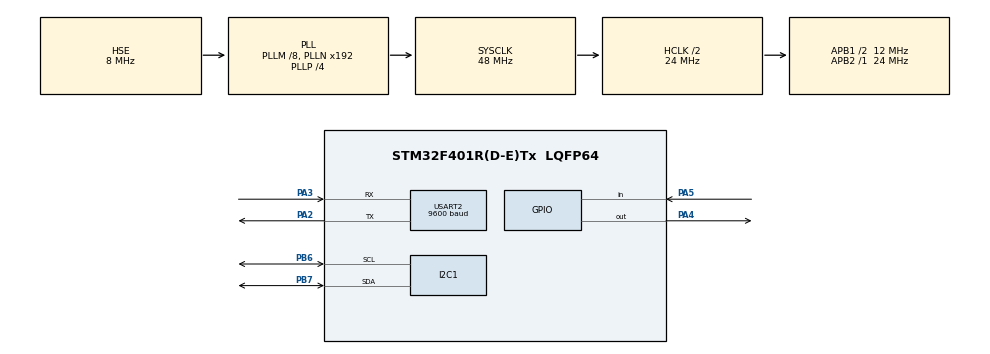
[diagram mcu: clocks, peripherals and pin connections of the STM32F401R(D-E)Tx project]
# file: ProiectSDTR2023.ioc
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FREERTOS.Tasks01=Task1,40,128,StartTask1,Default,NULL,Dynamic,NULL,NULL;Task2,24,128,StartTask2,Default,NULL,Dynamic,NULL,NULL
FREERTOS.configUSE_NEWLIB_REENTRANT=1
I2C1.I2C_Mode=I2C_Fast
Mcu.Family=STM32F4
Mcu.Name=STM32F401R(D-E)Tx
Mcu.Package=LQFP64
NVIC.PriorityGroup=NVIC_PRIORITYGROUP_4
NVIC.TIM5_IRQn=true\:15\:0\:false\:false\:true\:false\:false\:true\:true
NVIC.TimeBase=TIM5_IRQn
NVIC.TimeBaseIP=TIM5
PA13.Mode=Trace_Asynchronous_SW
PA13.Signal=SYS_JTMS-SWDIO
PA14.Mode=Trace_Asynchronous_SW
PA14.Signal=SYS_JTCK-SWCLK
PA2.Mode=Asynchronous
PA2.Signal=USART2_TX
PA3.Mode=Asynchronous
PA3.Signal=USART2_RX
PA4.Signal=GPIO_Output
PA5.Signal=GPIO_Input
PB3.Mode=Trace_Asynchronous_SW
PB3.Signal=SYS_JTDO-SWO
PB6.Mode=I2C
PB6.Signal=I2C1_SCL
PB7.Mode=I2C
PB7.Signal=I2C1_SDA
PH0\ -\ OSC_IN.Mode=HSE-External-Oscillator
PH0\ -\ OSC_IN.Signal=RCC_OSC_IN
PH1\ -\ OSC_OUT.Mode=HSE-External-Oscillator
PH1\ -\ OSC_OUT.Signal=RCC_OSC_OUT
ProjectManager.HeapSize=0x200
ProjectManager.StackSize=0x400
ProjectManager.TargetToolchain=STM32CubeIDE
RCC.48MHZClocksFreq_Value=48000000
RCC.AHBCLKDivider=RCC_SYSCLK_DIV2
RCC.AHBFreq_Value=24000000
RCC.APB1CLKDivider=RCC_HCLK_DIV2
RCC.APB1Freq_Value=12000000
RCC.APB1TimFreq_Value=24000000
RCC.APB2Freq_Value=24000000
RCC.APB2TimFreq_Value=24000000
RCC.CortexFreq_Value=24000000
RCC.HCLKFreq_Value=24000000
RCC.HSE_VALUE=8000000
RCC.HSI_VALUE=16000000
RCC.LSE_VALUE=32768
RCC.PLLM=8
RCC.PLLP=RCC_PLLP_DIV4
RCC.PLLSourceVirtual=RCC_PLLSOURCE_HSE
RCC.SYSCLKFreq_VALUE=48000000
RCC.SYSCLKSource=RCC_SYSCLKSOURCE_PLLCLK
RCC.VCOOutputFreq_Value=192000000
TIM1.Prescaler=71
USART2.BaudRate=9600
USART2.VirtualMode=VM_ASYNC
VP_FREERTOS_VS_CMSIS_V2.Mode=CMSIS_V2
VP_SYS_VS_tim5.Mode=TIM5
VP_TIM1_VS_ClockSourceINT.Mode=Internal
board=custom

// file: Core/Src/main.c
/* USER CODE BEGIN Header */
/**
  ******************************************************************************
  * @file           : main.c
  * @brief          : Main program body
  ******************************************************************************
  * @attention
  *
  * Copyright (c) 2023 STMicroelectronics.
  * All rights reserved.
  *
  * This software is licensed under terms that can be found in the LICENSE file
  * in the root directory of this software component.
  * If no LICENSE file comes with this software, it is provided AS-IS.
  *
  ******************************************************************************
  */
/* USER CODE END Header */
#include "main.h"
#include "cmsis_os.h"
#include "string.h"

/* USER CODE BEGIN Includes */
#include <stdio.h>

/* USER CODE END Includes */

I2C_HandleTypeDef hi2c1;

TIM_HandleTypeDef htim1;

UART_HandleTypeDef huart2;

/* Definitions for Task1 */
osThreadId_t Task1Handle;
const osThreadAttr_t Task1_attributes = {
  .name = "Task1",
  .stack_size = 128 * 4,
  .priority = (osPriority_t) osPriorityHigh,
};
/* Definitions for Task2 */
osThreadId_t Task2Handle;
const osThreadAttr_t Task2_attributes = {
  .name = "Task2",
  .stack_size = 128 * 4,
  .priority = (osPriority_t) osPriorityNormal,
};
/* USER CODE BEGIN PV */
osSemaphoreId_t distanceSemaphoreHandle;
osMessageQueueId_t distanceQueueHandle;
/* USER CODE END PV */

void SystemClock_Config(void);
static void MX_GPIO_Init(void);
static void MX_USART2_UART_Init(void);
static void MX_I2C1_Init(void);
static void MX_TIM1_Init(void);
void StartTask1(void *argument);
void StartTask2(void *argument);

int main(void)
{

  /* MCU Configuration--------------------------------------------------------*/

  /* Reset of all peripherals, Initializes the Flash interface and the Systick. */

	HAL_Init();

  /* Configure the system clock */
  SystemClock_Config();

  /* Initialize all configured peripherals */
  MX_GPIO_Init();
  MX_USART2_UART_Init();
  MX_I2C1_Init();
  MX_TIM1_Init();
  HAL_TIM_Base_Start(&htim1);

  /* Init scheduler */
  osKernelInitialize();

  /* USER CODE BEGIN RTOS_SEMAPHORES */
  distanceSemaphoreHandle = osSemaphoreNew(1, 0, NULL);
  /* USER CODE END RTOS_SEMAPHORES */

  /* USER CODE BEGIN RTOS_QUEUES */
  distanceQueueHandle = osMessageQueueNew(1, sizeof(uint32_t), NULL);
  /* USER CODE END RTOS_QUEUES */

  /* Create the thread(s) */
  /* creation of Task1 */
  Task1Handle = osThreadNew(StartTask1, NULL, &Task1_attributes);

  /* creation of Task2 */
  Task2Handle = osThreadNew(StartTask2, NULL, &Task2_attributes);

  /* Start scheduler */

  osKernelStart();

  /* We should never get here as control is now taken by the scheduler */
  /* Infinite loop */
  while (1)
  {

  }
}

void SystemClock_Config(void)
{
  RCC_OscInitTypeDef RCC_OscInitStruct = {0};
  RCC_ClkInitTypeDef RCC_ClkInitStruct = {0};

  /** Configure the main internal regulator output voltage
  */
  __HAL_RCC_PWR_CLK_ENABLE();
  __HAL_PWR_VOLTAGESCALING_CONFIG(PWR_REGULATOR_VOLTAGE_SCALE2);

  /** Initializes the RCC Oscillators according to the specified parameters
  * in the RCC_OscInitTypeDef structure.
  */
  RCC_OscInitStruct.OscillatorType = RCC_OSCILLATORTYPE_HSE;
  RCC_OscInitStruct.HSEState = RCC_HSE_ON;
  RCC_OscInitStruct.PLL.PLLState = RCC_PLL_ON;
  RCC_OscInitStruct.PLL.PLLSource = RCC_PLLSOURCE_HSE;
  RCC_OscInitStruct.PLL.PLLM = 8;
  RCC_OscInitStruct.PLL.PLLN = 192;
  RCC_OscInitStruct.PLL.PLLP = RCC_PLLP_DIV4;
  RCC_OscInitStruct.PLL.PLLQ = 4;
  if (HAL_RCC_OscConfig(&RCC_OscInitStruct) != HAL_OK)
  {
    Error_Handler();
  }

  /** Initializes the CPU, AHB and APB buses clocks
  */
  RCC_ClkInitStruct.ClockType = RCC_CLOCKTYPE_HCLK|RCC_CLOCKTYPE_SYSCLK
                              |RCC_CLOCKTYPE_PCLK1|RCC_CLOCKTYPE_PCLK2;
  RCC_ClkInitStruct.SYSCLKSource = RCC_SYSCLKSOURCE_PLLCLK;
  RCC_ClkInitStruct.AHBCLKDivider = RCC_SYSCLK_DIV2;
  RCC_ClkInitStruct.APB1CLKDivider = RCC_HCLK_DIV2;
  RCC_ClkInitStruct.APB2CLKDivider = RCC_HCLK_DIV1;

  if (HAL_RCC_ClockConfig(&RCC_ClkInitStruct, FLASH_LATENCY_0) != HAL_OK)
  {
    Error_Handler();
  }
}

static void MX_I2C1_Init(void)
{

  hi2c1.Instance = I2C1;
  hi2c1.Init.ClockSpeed = 400000;
  hi2c1.Init.DutyCycle = I2C_DUTYCYCLE_2;
  hi2c1.Init.OwnAddress1 = 0;
  hi2c1.Init.AddressingMode = I2C_ADDRESSINGMODE_7BIT;
  hi2c1.Init.DualAddressMode = I2C_DUALADDRESS_DISABLE;
  hi2c1.Init.OwnAddress2 = 0;
  hi2c1.Init.GeneralCallMode = I2C_GENERALCALL_DISABLE;
  hi2c1.Init.NoStretchMode = I2C_NOSTRETCH_DISABLE;
  if (HAL_I2C_Init(&hi2c1) != HAL_OK)
  {
    Error_Handler();
  }

}

static void MX_TIM1_Init(void)
{

  TIM_ClockConfigTypeDef sClockSourceConfig = {0};
  TIM_MasterConfigTypeDef sMasterConfig = {0};

  htim1.Instance = TIM1;
  htim1.Init.Prescaler = 71;
  htim1.Init.CounterMode = TIM_COUNTERMODE_UP;
  htim1.Init.Period = 65535;
  htim1.Init.ClockDivision = TIM_CLOCKDIVISION_DIV1;
  htim1.Init.RepetitionCounter = 0;
  htim1.Init.AutoReloadPreload = TIM_AUTORELOAD_PRELOAD_DISABLE;
  if (HAL_TIM_Base_Init(&htim1) != HAL_OK)
  {
    Error_Handler();
  }
  sClockSourceConfig.ClockSource = TIM_CLOCKSOURCE_INTERNAL;
  if (HAL_TIM_ConfigClockSource(&htim1, &sClockSourceConfig) != HAL_OK)
  {
    Error_Handler();
  }
  sMasterConfig.MasterOutputTrigger = TIM_TRGO_RESET;
  sMasterConfig.MasterSlaveMode = TIM_MASTERSLAVEMODE_DISABLE;
  if (HAL_TIMEx_MasterConfigSynchronization(&htim1, &sMasterConfig) != HAL_OK)
  {
    Error_Handler();
  }

}

static void MX_USART2_UART_Init(void)
{

  huart2.Instance = USART2;
  huart2.Init.BaudRate = 9600;
  huart2.Init.WordLength = UART_WORDLENGTH_8B;
  huart2.Init.StopBits = UART_STOPBITS_1;
  huart2.Init.Parity = UART_PARITY_NONE;
  huart2.Init.Mode = UART_MODE_TX;
  huart2.Init.HwFlowCtl = UART_HWCONTROL_NONE;
  huart2.Init.OverSampling = UART_OVERSAMPLING_16;
  if (HAL_UART_Init(&huart2) != HAL_OK)
  {
    Error_Handler();
  }

}

static void MX_GPIO_Init(void)
{
  GPIO_InitTypeDef GPIO_InitStruct = {0};

  /* GPIO Ports Clock Enable */
  __HAL_RCC_GPIOH_CLK_ENABLE();
  __HAL_RCC_GPIOA_CLK_ENABLE();
  __HAL_RCC_GPIOB_CLK_ENABLE();

  /*Configure GPIO pin Output Level */
  HAL_GPIO_WritePin(GPIOA, GPIO_PIN_4, GPIO_PIN_RESET);

  /*Configure GPIO pin : PA4 */
  GPIO_InitStruct.Pin = GPIO_PIN_4;
  GPIO_InitStruct.Mode = GPIO_MODE_OUTPUT_PP;
  GPIO_InitStruct.Pull = GPIO_NOPULL;
  GPIO_InitStruct.Speed = GPIO_SPEED_FREQ_LOW;
  HAL_GPIO_Init(GPIOA, &GPIO_InitStruct);

  /*Configure GPIO pin : PA5 */
  GPIO_InitStruct.Pin = GPIO_PIN_7;
  GPIO_InitStruct.Mode = GPIO_MODE_INPUT;
  GPIO_InitStruct.Pull = GPIO_NOPULL;
  HAL_GPIO_Init(GPIOA, &GPIO_InitStruct);

}

/* USER CODE BEGIN 4 */
volatile uint32_t calculatedDistance = 0;
/* USER CODE END 4 */

void StartTask1(void *argument)
{
  /* Infinite loop */
	uint32_t timer;
	uint32_t distanceTimer = 0;
  for (;;)
  {
	  //Trimite un puls pe pinul de Trigger: PA4
	 	   HAL_GPIO_WritePin(GPIOA, GPIO_PIN_4, GPIO_PIN_SET);
	 	   osDelay(1); // Wait for 1ms
	 	   HAL_GPIO_WritePin(GPIOA, GPIO_PIN_4, GPIO_PIN_RESET);

	 	   // Asteapta ca Echo sa fie activ: PA7
	 	   timer = HAL_GetTick();
	 	   while (HAL_GPIO_ReadPin(GPIOA, GPIO_PIN_7) == GPIO_PIN_RESET && (HAL_GetTick() - timer) < 10);

	 	   // Masoara timpul cat echo este high cu ajutorul TIM1
	 	   __HAL_TIM_SET_COUNTER(&htim1, 0);
	 	   timer = HAL_GetTick();
	 	   while (HAL_GPIO_ReadPin(GPIOA, GPIO_PIN_7) == GPIO_PIN_SET && (HAL_GetTick() - timer) < 50);
	 	   distanceTimer = __HAL_TIM_GET_COUNTER(&htim1);
	 	   timer = 0;
	 	   // calcularea distantei folosind urmatoarea formula: timpul cat semnalul de echo este high inmultit cu jumatate din viteza sunetului
	 	   calculatedDistance = (distanceTimer * 0.0343) ;

	 	   //Trimite distanta masurata catre task-ul 2 cu ajutorul unei cozi
	 	   uint32_t tempDistance = calculatedDistance;
	 	   osMessageQueuePut(distanceQueueHandle, &tempDistance, 0, 0);
	 	   osSemaphoreRelease(distanceSemaphoreHandle);

	 	   osDelay(500);
  }
  //osThreadExit();
}
  /* USER CODE END 5 */

void StartTask2(void *argument)
{
  /* USER CODE BEGIN StartTask2 */
  /* Infinite loop */
	uint32_t receivedDistance;
	char uartData[50];

	for(;;)
	{
	  //  Asteapta taskul anterior sa fie gata si elibereaza semaforul
	  osSemaphoreAcquire(distanceSemaphoreHandle, osWaitForever);

	  // Primeste disntanta de la coada
	  if (osMessageQueueGet(distanceQueueHandle, &receivedDistance, NULL, osWaitForever) == osOK)
	  {
	    //Scrie informatia de transmis in uartData si transmite prin UART: UART2 cu pinii PA2 si PA3
	    sprintf(uartData, "Distanta calculata aproximativa este: %lu cm\r\n", receivedDistance);
	    HAL_UART_Transmit(&huart2, (uint8_t *)uartData, strlen(uartData), 100);
	  }
	  else
	  {
	    // Handle error when receiving data from the queue
	    Error_Handler();
	  }

	  osDelay(1000); // Adjust as needed
	}

  }
  //osThreadExit();
  /* USER CODE END StartTask2 */

void HAL_TIM_PeriodElapsedCallback(TIM_HandleTypeDef *htim)
{
  if (htim->Instance == TIM5) {
    HAL_IncTick();
  }
}

void Error_Handler(void)
{
  __disable_irq();
  while (1)
  {
  }
}
